# S6E2CC register map
File version: 1.1
CPU: 
Registers are 8-bit, read-write, reset 0x0 unless marked. A register's access mark holds for its fields unless they carry their own. Offsets are from the block's base; [hi:lo] are bit positions; {n}, {i} and the like mark numbered series.

## DS — Low Power Consumption Mode
Base 0x40035100
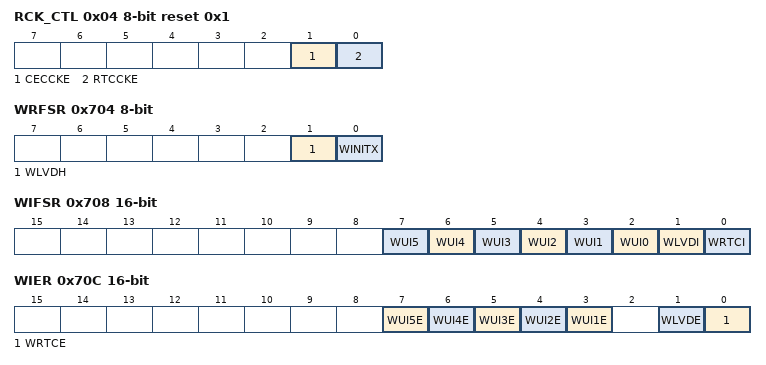
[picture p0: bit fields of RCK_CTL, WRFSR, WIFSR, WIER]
0x04 RCK_CTL reset 0x1 — Sub Clock Control Register
  [1] CECCKE — CEC clock control bit
  [0] RTCCKE — RTC clock control bit
0x700 PMD_CTL — RTC Mode Control Register
  [0] RTCE — RTC mode control bit
0x704 WRFSR — Deep Standby Return Cause Register 1
  [1] WLVDH — Low-voltage detection reset return bit
  [0] WINITX — INITX pin input reset return bit
0x708 WIFSR 16-bit ro — Deep Standby Return Cause Register 2
  [n+2] WUI{n} (n=0..5) — WKUP pin input return bit {n}
  [1] WLVDI — LVD interrupt return bit
  [0] WRTCI — RTC interrupt return bit
0x70C WIER 16-bit — Deep Standby Return Enable Register
  [n+2] WUI{n}E (n=1..5) — WKUP pin input return enable bit {n}
  [1] WLVDE — LVD interrupt return enable bit
  [0] WRTCE — RTC interrupt return enable bit
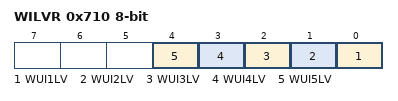
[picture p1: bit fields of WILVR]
0x710 WILVR — WKUP Pin Input Level Register
  [n-1] WUI{n}LV (n=1..5) — WKUP pin input level select bit {n}
0x714 DSRAMR — Deep Standby RAM Retention Register
  [1:0] SRAMR — On-chip SRAM retention control bits
{0x7FF+i} BUR{i:02} (i=1..16) — Backup Registers from {i}

## CRC — CRC Registers
Base 0x40039000
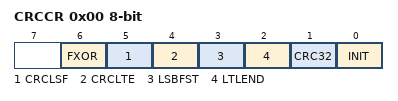
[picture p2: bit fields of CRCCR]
0x00 CRCCR — CRC Control Register
  [6] FXOR — Initialization bit
  [5] CRCLSF — Final XOR control bit
  [4] CRCLTE — CRC result bit-order setting bit
  [3] LSBFST — CRC result byte-order setting bit
  [2] LTLEND — Bit-order setting bit
  [1] CRC32 — Byte-order setting bit
  [0] INIT — CRC mode selection bit
0x04 CRCINIT 32-bit reset 0xFFFFFFFF — Initial Value Register
  [31:0] D — Initial value
0x08 CRCIN 32-bit — Input Data Register
  [31:0] D — Input data
0x0C CRCR 32-bit ro reset 0xFFFFFFFF — CRC Register
  [31:0] D — CRC Data

## WC — Watch Counter
Base 0x4003A000
0x00 WCRD ro — Watch Counter Read Register
  [5:0] CTR — Counter read bits
0x01 WCRL — Watch Counter Reload Register
  [5:0] RLC — Counter reload value setting bits
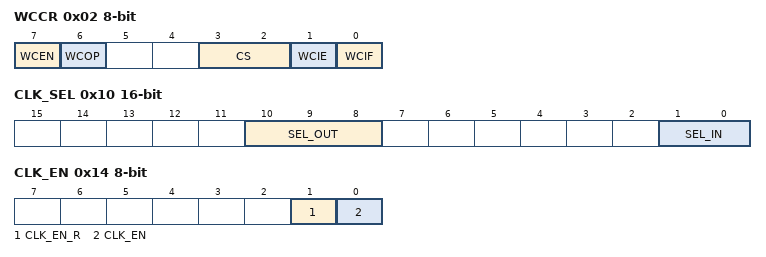
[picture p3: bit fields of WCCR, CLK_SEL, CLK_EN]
0x02 WCCR — Watch Counter Control Register
  [7] WCEN — Watch counter operation enable bit
  [6] WCOP ro — Watch counter operating state flag
  [3:2] CS — Count clock select bits
  [1] WCIE — Interrupt request enable bit
  [0] WCIF — Interrupt request flag bit
0x10 CLK_SEL 16-bit — Clock Selection Register
  [10:8] SEL_OUT — Output clock selection bit
  [1:0] SEL_IN — Input clock selection bit
0x14 CLK_EN — Division Clock Enable Register
  [1] CLK_EN_R — Division clock enable read bit
  [0] CLK_EN — Division clock enable bit

## LCR — Low-speed CR Prescaler
Base 0x4003C000
0x00 LCR_PRSLD — Low-speed CR Prescaler Control Register
  [5:0] LCR_PRSLD — Low-speed CR Prescaler Load

## PLL_CONTROL — Main PLL Control
Base 0x4003C800
0x00 SSCTL1 32-bit (reset mask 0x31)
0x04 SSCTL2 32-bit (reset mask 0x3FF)

## USBETHERCLK — USB/Ethernet Clock
Base 0x40036000
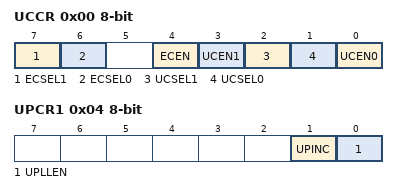
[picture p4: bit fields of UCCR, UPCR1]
0x00 UCCR (reset mask 0x7F) — USB/Ethernet-PLL Clock Control Register
  [7] ECSEL1 — Ethernet clock selection bit 1
  [6] ECSEL0 — Ethernet clock selection bit 0
  [4] ECEN — Ethernet clock output enable bit
  [3] UCEN1 — USB1 clock output enable bit
  [2] UCSEL1 — USB1 clock selection bit
  [1] UCSEL0 — USB0 clock selection bit
  [0] UCEN0 — USB0 clock output enable bit
0x04 UPCR1 — USB/Ethernet-PLL Control Register 1
  [1] UPINC — USB/Ethernet-PLL input clock selection bit
  [0] UPLLEN — USB/Ethernet-PLL oscillation enable bit
0x08 UPCR2 — USB/Ethernet-PLL Control Register 2
  [2:0] UPOWT — USB/Ethernet-PLL oscillation stabilization wait time setting bit
0x0C UPCR3 — USB/Ethernet-PLL Control Register 3
  [4:0] UPLLK — Frequency division ratio (K) setting bit of the USB/Ethernet-PLL clock
0x10 UPCR4 reset 0x3B — USB/Ethernet-PLL Control Register 4
  [6:0] UPLLN — Frequency division ratio (N) setting bit of the USB/Ethernet-PLL clock
0x14 UP_STR ro — USB/Ethernet-PLL Status Register
  [0] UPRDY — USB/Ethernet-PLL oscillation stabilization bit
0x18 UPINT_ENR — USB/Ethernet-PLL Interrupt Source Enable Register
  [0] UPCSE — USB/Ethernet-PLL oscillation stabilization wait complete interrupt enable bit
0x1C UPINT_CLR wo — USB/Ethernet-PLL Interrupt Source Clear Register
  [0] UPCSC — USB/Ethernet-PLL oscillation stabilization interrupt source clear bit
0x20 UPINT_STR ro — ERROR!!!!!!!!!!!!!!!!!!!!
  [0] UPCSI
0x24 UPCR5 reset 0x4 — ERROR!!!!!!!!!!!!!!!!!!!!
  [3:0] UPLLM
0x28 UPCR6 reset 0x2 — ERROR!!!!!!!!!!!!!!!!!!!!
  [3:0] UBSR
0x2C UPCR7 — ERROR!!!!!!!!!!!!!!!!!!!!
  [0] EPLLEN
0x30 USBEN0 — ERROR!!!!!!!!!!!!!!!!!!!!
  [0] USBEN0
0x34 USBEN1 — ERROR!!!!!!!!!!!!!!!!!!!!
  [0] USBEN1
